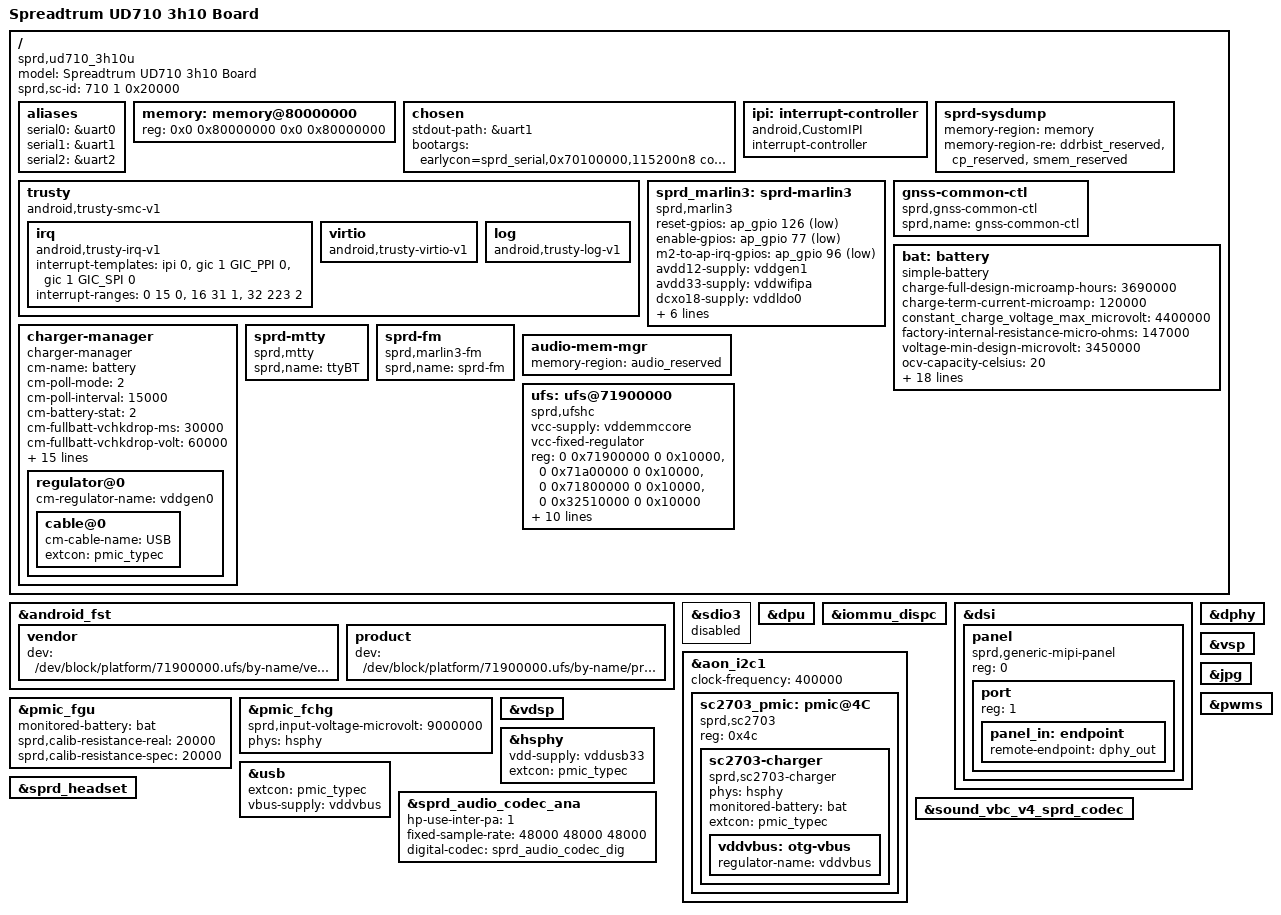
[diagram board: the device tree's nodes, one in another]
/*
 * Spreadtrum Roc1 board DTS file
 *
 * Copyright (C) 2018, Spreadtrum Communications Inc.
 *
 * This file is licensed under a dual GPLv2 or X11 license.
 */
/dts-v1/;

#include <dt-bindings/gpio/gpio.h>

#include "ud710.dtsi"
#include "ud710-common.dtsi"
#include "ud710-3h10-modem.dtsi"
#include "sprd-sound-fe-be.dtsi"
#include "sc2730.dtsi"
#include "lcd/lcd_td4310_truly_mipi_fhd.dtsi"

/ {
	model = "Spreadtrum UD710 3h10 Board";

	compatible = "sprd,ud710_3h10u", "sprd,ud710";

	sprd,sc-id = <710 1 0x20000>;

	aliases {
		serial0 = &uart0;
		serial1 = &uart1;
		serial2 = &uart2;
	};

	memory: memory@80000000 {
		device_type = "memory";
		reg = <0x0 0x80000000 0x0 0x80000000>;
	};

	chosen {
		stdout-path = &uart1;
		bootargs = "earlycon=sprd_serial,0x70100000,115200n8 console=ttyS1,115200n8 loglevel=8 maxcpus=1 init=/init root=/dev/sdc31 rootfstype=ext4 rw rootwait androidboot.hardware=ud710_3h10u androidboot.selinux=permissive";
	};

	ipi: interrupt-controller {
		compatible = "android,CustomIPI";
		#interrupt-cells = <1>;
		interrupt-controller;
	};

	trusty {
		compatible = "android,trusty-smc-v1";

		irq {
			compatible = "android,trusty-irq-v1";
			interrupt-templates = <&ipi 0>,
						<&gic 1 GIC_PPI 0>,
						<&gic 1 GIC_SPI 0>;
			interrupt-ranges = < 0  15 0>,
						<16  31 1>,
						<32 223 2>;
		};

		virtio {
			compatible = "android,trusty-virtio-v1";
		};

		log {
			compatible = "android,trusty-log-v1";
		};
	};

	sprd-sysdump {
		memory-region = <&memory>;
		memory-region-re = <&ddrbist_reserved>, <&cp_reserved>, <&smem_reserved>;
	};

	sprd_marlin3: sprd-marlin3 {
		compatible = "sprd,marlin3";
		reset-gpios = <&ap_gpio 126 GPIO_ACTIVE_LOW>;
		enable-gpios = <&ap_gpio 77 GPIO_ACTIVE_LOW>;
		m2-to-ap-irq-gpios = <&ap_gpio 96 GPIO_ACTIVE_LOW>;
		/* no need config dvdd12 because of share vddmem to DDR */
		avdd12-supply = <&vddgen1>;
		avdd33-supply = <&vddwifipa>;
		dcxo18-supply = <&vddldo0>;
		clock-names = "clk_32k","source","enable";
		clocks = <&aon_clk CLK_AON_AUX0>,
			 <&ext_32k>,
			 <&aonapb_gate CLK_AUX0_EB>;
		sprd,btwf-file-name = "/dev/block/platform/soc/soc:ap-apb/71400000.sdio/by-name/wcnmodem";
		sprd,gnss-file-name = "/dev/block/platform/soc/soc:ap-apb/71400000.sdio/by-name/gnssmodem";
	};

	gnss-common-ctl {
		compatible = "sprd,gnss-common-ctl";
		sprd,name = "gnss-common-ctl";
	};

	bat: battery {
		compatible = "simple-battery";
		charge-full-design-microamp-hours = <3690000>;
		charge-term-current-microamp = <120000>;
		constant_charge_voltage_max_microvolt = <4400000>;
		factory-internal-resistance-micro-ohms = <147000>;
		voltage-min-design-microvolt = <3450000>;
		ocv-capacity-celsius = <20>;
		ocv-capacity-table-0 = <4360000 100>, <4317000 95>, <4258000 90>,
					<4200000 85>, <4145000 80>, <4092000 75>,
					<4047000 70>, <3990000 65>, <3955000 60>,
					<3900000 55>, <3861000 50>, <3834000 45>,
					<3813000 40>, <3796000 35>, <3783000 30>,
					<3770000 25>, <3752000 20>, <3730000 15>,
					<3698000 10>, <3687000 5>, <3400000 0>;
		voltage-temp-table = <1052000 750>, <953000 800>, <858000 850>,
				      <762000 900>, <671000 950>,<584000 1000>,
				      <504000 1050>, <434000 1100>, <372000 1150>,
				      <318000 1200>,<271000 1250>, <234000 1300>,
				      <198000 1350>, <165000 1400>, <140000 1450>,
				      <119000 1500>, <104000 1550>, <88000 1600>;
		charge-sdp-current-microamp = <500000 500000>;
		charge-dcp-current-microamp = <2000000 3000000>;
		charge-cdp-current-microamp = <1500000 1500000>;
		charge-unknown-current-microamp = <500000 500000>;
	};

	charger-manager {
		compatible = "charger-manager";
		cm-name = "battery";
		cm-poll-mode = <2>;
		cm-poll-interval = <15000>;
		cm-battery-stat = <2>;

		cm-fullbatt-vchkdrop-ms = <30000>;
		cm-fullbatt-vchkdrop-volt = <60000>;
		cm-fullbatt-voltage = <4380000>;
		cm-fullbatt-current = <120000>;
		cm-fullbatt-capacity = <100>;

		cm-num-chargers = <1>;
		cm-chargers = "sc2703_charger";
		cm-fuel-gauge = "sc27xx-fgu";

		/* in deci centigrade */
		cm-battery-cold = <50>;
		cm-battery-cold-in-minus;
		cm-battery-hot = <800>;
		cm-battery-temp-diff = <100>;

		/* Allow charging for 6hr */
		cm-charging-max = <18000000>;

		/* the interval to feed charger watchdog */
		cm-wdt-interval = <60>;

		/* drop voltage in microVolts to allow shutdown */
		cm-shutdown-voltage = <3100000>;

		/* when 99% of the time is exceeded, it will be forced to 100% */
		cm-tickle-time-out = <1500>;

		/* how much time to allow capacity change */
		cm-one-cap-time = <30>;

		regulator@0 {
			cm-regulator-name = "vddgen0";
			cable@0 {
				cm-cable-name = "USB";
				extcon = <&pmic_typec>;
			};
		};
	};

	sprd-mtty {
		compatible = "sprd,mtty";
		sprd,name = "ttyBT";
	};

	sprd-fm {
		compatible = "sprd,marlin3-fm";
		sprd,name = "sprd-fm";
	};

	audio-mem-mgr {
		memory-region = <&audio_reserved>;
	};

	ufs: ufs@71900000 {
		compatible  = "sprd,ufshc";
		vcc-supply = <&vddemmccore>;
		vcc-fixed-regulator;
		reg = <0 0x71900000 0 0x10000>,
		      <0 0x71a00000 0 0x10000>,
		      <0 0x71800000 0 0x10000>,
		      <0 0x32510000 0 0x10000>;
		reg-names = "ufshci_reg",
			    "ufsutp_reg",
			    "unipro_reg",
			    "ufs_ao_reg";
		syscons = <&aon_apb_regs REG_AON_APB_APB_EB1 MASK_AON_APB_UFS_AO_EB>,
			  <&ap_apb_regs REG_AP_APB_APB_EB1 (MASK_AP_APB_UFS_UTP_EB | MASK_AP_APB_UFS_HCI_EB | MASK_AP_APB_UFS_UNIPRO_EB | MASK_AP_APB_UFS_EB)>,
			  <&ap_apb_regs REG_AP_APB_APB_RST (MASK_AP_APB_UFS_UTP_SOFT_RST | MASK_AP_APB_UFS_HCI_SOFT_RST | MASK_AP_APB_UFS_UNIPRO_SOFT_RST | MASK_AP_APB_UFS_SOFT_RST)>,
			  <&anlg_phy_g1_regs REG_ANLG_PHY_G1_ANALOG_MIPI_MPHY_1T1R_MPHY_APB_REG MASK_ANLG_PHY_G1_ANALOG_MIPI_MPHY_1T1R_MPHY_APB_PRESETN>,
			  <&aon_apb_regs REG_AON_APB_APB_RST1 MASK_AON_APB_UFS_AO_SOFT_RST>;
		syscon-names = "aon_apb_ufs_en",
			       "ap_apb_ufs_en",
			       "ap_apb_ufs_rst",
			       "anlg_mphy_ufs_rst",
			       "aon_apb_ufs_rst";
		interrupts = <GIC_SPI 140 IRQ_TYPE_LEVEL_HIGH>;
		status = "okay";
	};
};

&android_fst {
	vendor {
		dev = "/dev/block/platform/71900000.ufs/by-name/vendor";
	};
	product {
		dev = "/dev/block/platform/71900000.ufs/by-name/product";
	};
};

&sdio3 {
	status = "disabled";
};

&dpu {
	status = "okay";
};

&iommu_dispc {
	status = "okay";
};

&dsi {
	status = "okay";
	#address-cells = <1>;
	#size-cells = <0>;

	panel {
		compatible = "sprd,generic-mipi-panel";
		#address-cells = <1>;
		#size-cells = <0>;
		reg = <0>;

		port {
			reg = <1>;
			panel_in: endpoint {
				remote-endpoint = <&dphy_out>;
			};
		};
	};
};


&dphy {
	status = "okay";
};

&aon_i2c1 {
	status = "okay";
	clock-frequency = <400000>;

	sc2703_pmic: pmic@4C {
		compatible = "sprd,sc2703";
		reg = <0x4c>;
		sc2703-charger {
			compatible = "sprd,sc2703-charger";
			phys = <&hsphy>;
			monitored-battery = <&bat>;
			extcon = <&pmic_typec>;
			vddvbus:otg-vbus {
				regulator-name = "vddvbus";
			};
		};
	};
};

&pmic_fgu {
	monitored-battery = <&bat>;
	sprd,calib-resistance-real = <20000>;
	sprd,calib-resistance-spec = <20000>;
};

&pmic_fchg {
	sprd,input-voltage-microvolt = <9000000>;
	phys = <&hsphy>;
};

&vsp {
	status = "okay";
};

&jpg {
	status = "okay";
};

&pwms {
	status = "okay";
};

&vdsp {
	status = "okay";
};

&hsphy {
	vdd-supply = <&vddusb33>;
	extcon = <&pmic_typec>;
};

&usb {
	extcon = <&pmic_typec>;
	vbus-supply = <&vddvbus>;
};

&sprd_headset {
	status = "okay";
};

&sprd_audio_codec_ana {
	status = "okay";
	hp-use-inter-pa = <1>;
	fixed-sample-rate = <48000 48000 48000>;
	digital-codec = <&sprd_audio_codec_dig>;
};

&sound_vbc_v4_sprd_codec {
	status = "okay";
};
